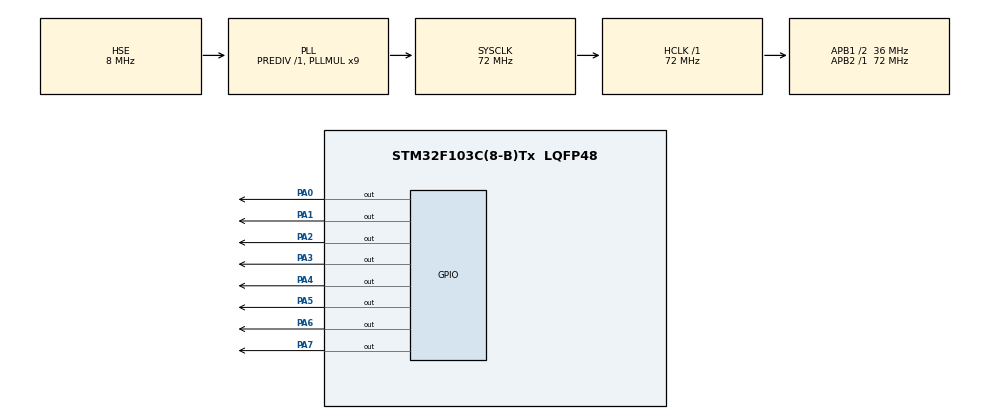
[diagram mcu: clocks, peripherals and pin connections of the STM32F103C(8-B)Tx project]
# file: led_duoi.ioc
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FREERTOS.Tasks01=task_1,16,128,task_1_function,Default,NULL,Dynamic,NULL,NULL;task_2,16,128,task_2_function,Default,NULL,Dynamic,NULL,NULL
Mcu.Family=STM32F1
Mcu.Name=STM32F103C(8-B)Tx
Mcu.Package=LQFP48
NVIC.PriorityGroup=NVIC_PRIORITYGROUP_4
PA0-WKUP.Signal=GPIO_Output
PA1.Signal=GPIO_Output
PA13.Mode=Serial_Wire
PA13.Signal=SYS_JTMS-SWDIO
PA14.Mode=Serial_Wire
PA14.Signal=SYS_JTCK-SWCLK
PA2.Signal=GPIO_Output
PA3.Signal=GPIO_Output
PA4.Signal=GPIO_Output
PA5.Signal=GPIO_Output
PA6.Signal=GPIO_Output
PA7.Signal=GPIO_Output
PD0-OSC_IN.Mode=HSE-External-Oscillator
PD0-OSC_IN.Signal=RCC_OSC_IN
PD1-OSC_OUT.Mode=HSE-External-Oscillator
PD1-OSC_OUT.Signal=RCC_OSC_OUT
ProjectManager.HeapSize=0x200
ProjectManager.StackSize=0x400
ProjectManager.TargetToolchain=STM32CubeIDE
RCC.AHBFreq_Value=72000000
RCC.APB1CLKDivider=RCC_HCLK_DIV2
RCC.APB1Freq_Value=36000000
RCC.APB1TimFreq_Value=72000000
RCC.APB2Freq_Value=72000000
RCC.APB2TimFreq_Value=72000000
RCC.HCLKFreq_Value=72000000
RCC.PLLMUL=RCC_PLL_MUL9
RCC.PLLSourceVirtual=RCC_PLLSOURCE_HSE
RCC.SYSCLKFreq_VALUE=72000000
RCC.SYSCLKSource=RCC_SYSCLKSOURCE_PLLCLK
RCC.USBFreq_Value=72000000
VP_FREERTOS_VS_CMSIS_V2.Mode=CMSIS_V2
board=custom

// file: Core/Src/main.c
/* USER CODE BEGIN Header */
/**
  ******************************************************************************
  * @file           : main.c
  * @brief          : Main program body
  ******************************************************************************
  * @attention
  *
  * Copyright (c) 2023 STMicroelectronics.
  * All rights reserved.
  *
  * This software is licensed under terms that can be found in the LICENSE file
  * in the root directory of this software component.
  * If no LICENSE file comes with this software, it is provided AS-IS.
  *
  ******************************************************************************
  */
/* USER CODE END Header */
#include "main.h"
#include "cmsis_os2.h"

/* Definitions for task_1 */
osThreadId_t task_1Handle;
const osThreadAttr_t task_1_attributes = {
  .name = "task_1",
  .stack_size = 128 * 4,
  .priority = (osPriority_t) osPriorityBelowNormal,
};
/* Definitions for task_2 */
osThreadId_t task_2Handle;
const osThreadAttr_t task_2_attributes = {
  .name = "task_2",
  .stack_size = 128 * 4,
  .priority = (osPriority_t) osPriorityBelowNormal,
};

void SystemClock_Config(void);
static void MX_GPIO_Init(void);
void task_1_function(void *argument);
void task_2_function(void *argument);

int main(void)
{

  /* MCU Configuration--------------------------------------------------------*/

  /* Reset of all peripherals, Initializes the Flash interface and the Systick. */
  HAL_Init();

  /* Configure the system clock */
  SystemClock_Config();

  /* Initialize all configured peripherals */
  MX_GPIO_Init();

  /* Init scheduler */
  osKernelInitialize();

  /* Create the thread(s) */
  /* creation of task_1 */
  task_1Handle = osThreadNew(task_1_function, NULL, &task_1_attributes);

  /* creation of task_2 */
  task_2Handle = osThreadNew(task_2_function, NULL, &task_2_attributes);

  /* Start scheduler */
  osKernelStart();

  /* We should never get here as control is now taken by the scheduler */
  /* Infinite loop */
  while (1)
  {
	HAL_GPIO_TogglePin(GPIOA, GPIO_PIN_0);
	HAL_Delay(500);
  }
}

void SystemClock_Config(void)
{
  RCC_OscInitTypeDef RCC_OscInitStruct = {0};
  RCC_ClkInitTypeDef RCC_ClkInitStruct = {0};

  /** Initializes the RCC Oscillators according to the specified parameters
  * in the RCC_OscInitTypeDef structure.
  */
  RCC_OscInitStruct.OscillatorType = RCC_OSCILLATORTYPE_HSE;
  RCC_OscInitStruct.HSEState = RCC_HSE_ON;
  RCC_OscInitStruct.HSEPredivValue = RCC_HSE_PREDIV_DIV1;
  RCC_OscInitStruct.HSIState = RCC_HSI_ON;
  RCC_OscInitStruct.PLL.PLLState = RCC_PLL_ON;
  RCC_OscInitStruct.PLL.PLLSource = RCC_PLLSOURCE_HSE;
  RCC_OscInitStruct.PLL.PLLMUL = RCC_PLL_MUL9;
  if (HAL_RCC_OscConfig(&RCC_OscInitStruct) != HAL_OK)
  {
    Error_Handler();
  }

  /** Initializes the CPU, AHB and APB buses clocks
  */
  RCC_ClkInitStruct.ClockType = RCC_CLOCKTYPE_HCLK|RCC_CLOCKTYPE_SYSCLK
                              |RCC_CLOCKTYPE_PCLK1|RCC_CLOCKTYPE_PCLK2;
  RCC_ClkInitStruct.SYSCLKSource = RCC_SYSCLKSOURCE_PLLCLK;
  RCC_ClkInitStruct.AHBCLKDivider = RCC_SYSCLK_DIV1;
  RCC_ClkInitStruct.APB1CLKDivider = RCC_HCLK_DIV2;
  RCC_ClkInitStruct.APB2CLKDivider = RCC_HCLK_DIV1;

  if (HAL_RCC_ClockConfig(&RCC_ClkInitStruct, FLASH_LATENCY_2) != HAL_OK)
  {
    Error_Handler();
  }
}

static void MX_GPIO_Init(void)
{
  GPIO_InitTypeDef GPIO_InitStruct = {0};

  /* GPIO Ports Clock Enable */
  __HAL_RCC_GPIOD_CLK_ENABLE();
  __HAL_RCC_GPIOA_CLK_ENABLE();

  /*Configure GPIO pin Output Level */
  HAL_GPIO_WritePin(GPIOA, GPIO_PIN_0|GPIO_PIN_1|GPIO_PIN_2|GPIO_PIN_3
                          |GPIO_PIN_4|GPIO_PIN_5|GPIO_PIN_6|GPIO_PIN_7, GPIO_PIN_RESET);

  /*Configure GPIO pins : PA0 PA1 PA2 PA3
                           PA4 PA5 PA6 PA7 */
  GPIO_InitStruct.Pin = GPIO_PIN_0|GPIO_PIN_1|GPIO_PIN_2|GPIO_PIN_3
                          |GPIO_PIN_4|GPIO_PIN_5|GPIO_PIN_6|GPIO_PIN_7;
  GPIO_InitStruct.Mode = GPIO_MODE_OUTPUT_PP;
  GPIO_InitStruct.Pull = GPIO_NOPULL;
  GPIO_InitStruct.Speed = GPIO_SPEED_FREQ_LOW;
  HAL_GPIO_Init(GPIOA, &GPIO_InitStruct);

}

void task_1_function(void *argument)
{

  /* USER CODE BEGIN 5 */
  /* Infinite loop */
	for(;;)
		  {
			  for (int i = 0; i < 8; i++) {
		      if(i==0)
		      {
		         HAL_GPIO_WritePin(GPIOA, 0x01 << i, 1);
		         osDelay(20);
		         HAL_GPIO_WritePin(GPIOA, 0x01 << i , 0);
		      }
		      else if(i == 1)
		      {
		         for(int j = 0; j<20;j++)
		         {
		            HAL_GPIO_WritePin(GPIOA, 0x01 << i, 1);
		            osDelay(5);
		            HAL_GPIO_WritePin(GPIOA, 0x01 << (i-1), 1);
		            osDelay(1);
		            HAL_GPIO_WritePin(GPIOA, 0x01 << i , 0);
		            HAL_GPIO_WritePin(GPIOA, 0x01 << (i-1) , 0);
		            osDelay(1);
		         }
		      }
		      else{
		         for(int j = 0; j<20;j++)
		         {
		               HAL_GPIO_WritePin(GPIOA, 0x01 << i, 1);
		               osDelay(1);
		               HAL_GPIO_WritePin(GPIOA, 0x01 << (i-1), 1);
		               osDelay(1);
		               HAL_GPIO_WritePin(GPIOA, 0x01 << (i-2), 1);
		               osDelay(1);
		               HAL_GPIO_WritePin(GPIOA, 0x01 << i , 0);
		               HAL_GPIO_WritePin(GPIOA, 0x01 << (i-1) , 0);
		               HAL_GPIO_WritePin(GPIOA, 0x01 << (i-2), 0);
		               osDelay(2);

		         }
		      }
		   }
		   GPIOA->BSRR = GPIO_PIN_All  << 16u;
		   osDelay(500);
		  }
//	for(;;){
//	  for(int i = 0; i < 4; i++)
//	  {
//		  HAL_GPIO_WritePin(GPIOA, GPIO_PIN_0 << i , 1);
//		  osDelay(1000);
//	  }
//	  GPIOA->BSRR = (uint32_t)GPIO_PIN_All << 16u;
//	  osDelay(1000);
//	  for(int i = 0; i < 4; i++)
//	  	  {
//	  		  HAL_GPIO_WritePin(GPIOA, GPIO_PIN_3 >> i , 1);
//	  		  osDelay(1000);
//	  	  }
//	  GPIOA->BSRR = (uint32_t)GPIO_PIN_All << 16u;
//	 	  osDelay(1000);
//  /* USER CODE END 5 */
	//  }
}
void task_2_function(void *argument)
{
  /* USER CODE BEGIN task_2_function */
  /* Infinite loop */
	while(1){
//		HAL_GPIO_TogglePin(GPIOA, GPIO_PIN_0);
//		osDelay(500);

	}
//  for(;;)
//  {
//	  for(int i = 0; i < 4; i++)
//	  	  {
//	  		  HAL_GPIO_WritePin(GPIOB, GPIO_PIN_6 >> i , 1);
//	  		  osDelay(1000);
//	  		// HAL_GPIO_WritePin(GPIOB, GPIO_PIN_6 >> i , 0);
//	  	  }
//	  	  GPIOB->BSRR = (uint32_t)GPIO_PIN_All << 16u;
//	  	  osDelay(1000);
//	  	  for(int i = 0; i < 4; i++)
//	  	  	  {
//	  	  		  HAL_GPIO_WritePin(GPIOB, GPIO_PIN_3 << i , 1);
//	  	  		  osDelay(1000);
//	  	  	  }
//	  	  GPIOB->BSRR = (uint32_t)GPIO_PIN_All << 16u;
//	  	 	  osDelay(1000);
//  }
//	 for(;;)
//	  {
//		 HAL_GPIO_TogglePin(GPIOA, GPIO_PIN_0);
//		 for(uint32_t i = 0; i< 10000;i++){
//
//		 }
		 //osDelay(500);
//		  for(int i = 0; i < 6; i++)
//		  	  {
//		  		  HAL_GPIO_WritePin(GPIOA, (GPIO_PIN_0 << i) | (GPIO_PIN_0 << (i+2)), 1);
//		  		  osDelay(1000);
//			  	  GPIOA->BSRR = (uint32_t)GPIO_PIN_All << 16u;
//			  	  osDelay(1000);
//
//		  	  }
//		  for(int i = 0; i < 6; i++)
//		  		  	  {
//		  		  		  HAL_GPIO_WritePin(GPIOA, (GPIO_PIN_7  >> i) | (GPIO_PIN_7 >> (i+2)), 1);
//		  		  		  osDelay(1000);
//		  			  	  GPIOA->BSRR = (uint32_t)GPIO_PIN_All << 16u;
//		  			  	  osDelay(1000);
//
//		  		  	  }
//	  }
  /* USER CODE END task_2_function */
}

void Error_Handler(void)
{
  __disable_irq();
  while (1)
  {
  }
}
